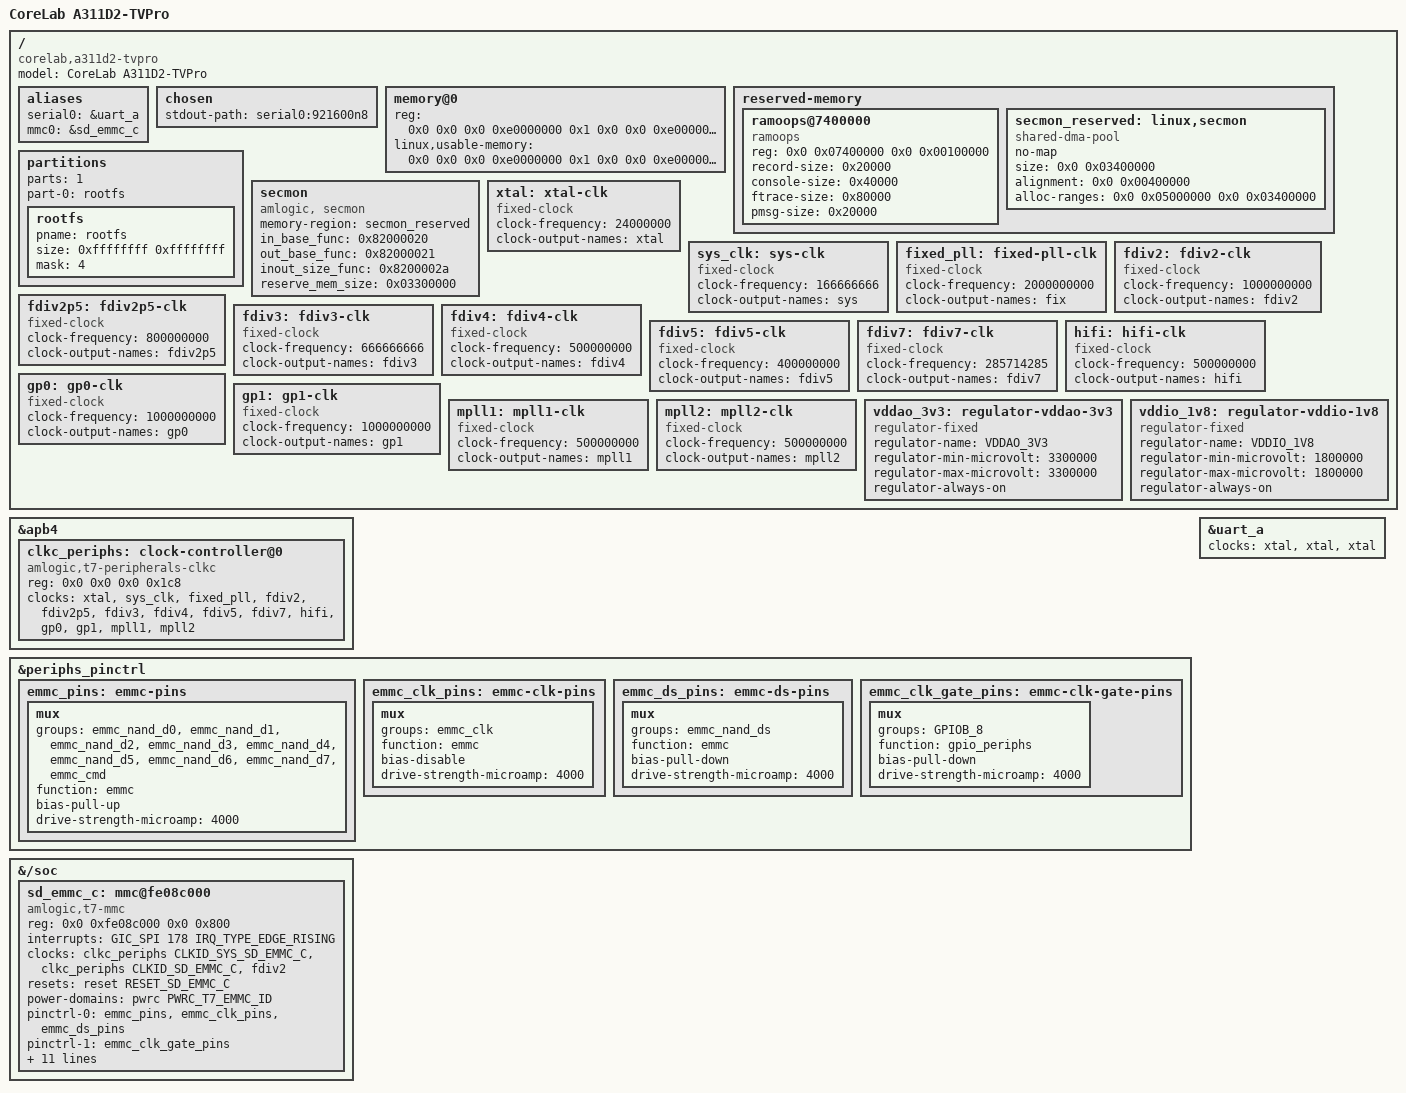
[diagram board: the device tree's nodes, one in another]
// SPDX-License-Identifier: (GPL-2.0+ OR MIT)
/*
 * Minimal Linux v7.1 TVPRO bring-up device tree.
 *
 * This intentionally starts from upstream T7 support and only carries the
 * board data needed before enabling the 5.15 vendor multimedia stack.
 */

/dts-v1/;

#include <dt-bindings/clock/amlogic,t7-peripherals-clkc.h>
#include <dt-bindings/gpio/gpio.h>
#include "amlogic-t7.dtsi"

/ {
	model = "CoreLab A311D2-TVPro";
	compatible = "corelab,a311d2-tvpro", "amlogic,a311d2", "amlogic,t7";

	aliases {
		serial0 = &uart_a;
		mmc0 = &sd_emmc_c;
	};

	chosen {
		stdout-path = "serial0:921600n8";
	};

	memory@0 {
		device_type = "memory";
		reg = <0x0 0x0 0x0 0xe0000000
		       0x1 0x0 0x0 0xe0000000
		       0x2 0x0 0x0 0x40000000>; /* 8 GB */
		linux,usable-memory = <0x0 0x0 0x0 0xe0000000
				       0x1 0x0 0x0 0xe0000000
				       0x2 0x0 0x0 0x40000000>;
	};

	reserved-memory {
		#address-cells = <2>;
		#size-cells = <2>;
		ranges;

		ramoops@7400000 {
			compatible = "ramoops";
			reg = <0x0 0x07400000 0x0 0x00100000>;
			record-size = <0x20000>;
			console-size = <0x40000>;
			ftrace-size = <0x80000>;
			pmsg-size = <0x20000>;
		};

		/* Vendor U-Boot hardcodes this node path during rsvmem check. */
		secmon_reserved: linux,secmon {
			compatible = "shared-dma-pool";
			no-map;
			size = <0x0 0x03400000>;
			alignment = <0x0 0x00400000>;
			alloc-ranges = <0x0 0x05000000 0x0 0x03400000>;
		};
	};

	partitions: partitions {
		parts = <1>;
		part-0 = <&rootfs>;

		rootfs: rootfs {
			pname = "rootfs";
			size = <0xffffffff 0xffffffff>;
			mask = <4>;
		};
	};

	secmon {
		compatible = "amlogic, secmon";
		memory-region = <&secmon_reserved>;
		in_base_func = <0x82000020>;
		out_base_func = <0x82000021>;
		inout_size_func = <0x8200002a>;
		reserve_mem_size = <0x03300000>;
	};

	xtal: xtal-clk {
		compatible = "fixed-clock";
		clock-frequency = <24000000>;
		clock-output-names = "xtal";
		#clock-cells = <0>;
	};

	/* Temporary parent clocks until the full T7 SCMI/PLL map is safe to enable. */
	sys_clk: sys-clk {
		compatible = "fixed-clock";
		clock-frequency = <166666666>;
		clock-output-names = "sys";
		#clock-cells = <0>;
	};

	fixed_pll: fixed-pll-clk {
		compatible = "fixed-clock";
		clock-frequency = <2000000000>;
		clock-output-names = "fix";
		#clock-cells = <0>;
	};

	fdiv2: fdiv2-clk {
		compatible = "fixed-clock";
		clock-frequency = <1000000000>;
		clock-output-names = "fdiv2";
		#clock-cells = <0>;
	};

	fdiv2p5: fdiv2p5-clk {
		compatible = "fixed-clock";
		clock-frequency = <800000000>;
		clock-output-names = "fdiv2p5";
		#clock-cells = <0>;
	};

	fdiv3: fdiv3-clk {
		compatible = "fixed-clock";
		clock-frequency = <666666666>;
		clock-output-names = "fdiv3";
		#clock-cells = <0>;
	};

	fdiv4: fdiv4-clk {
		compatible = "fixed-clock";
		clock-frequency = <500000000>;
		clock-output-names = "fdiv4";
		#clock-cells = <0>;
	};

	fdiv5: fdiv5-clk {
		compatible = "fixed-clock";
		clock-frequency = <400000000>;
		clock-output-names = "fdiv5";
		#clock-cells = <0>;
	};

	fdiv7: fdiv7-clk {
		compatible = "fixed-clock";
		clock-frequency = <285714285>;
		clock-output-names = "fdiv7";
		#clock-cells = <0>;
	};

	hifi: hifi-clk {
		compatible = "fixed-clock";
		clock-frequency = <500000000>;
		clock-output-names = "hifi";
		#clock-cells = <0>;
	};

	gp0: gp0-clk {
		compatible = "fixed-clock";
		clock-frequency = <1000000000>;
		clock-output-names = "gp0";
		#clock-cells = <0>;
	};

	gp1: gp1-clk {
		compatible = "fixed-clock";
		clock-frequency = <1000000000>;
		clock-output-names = "gp1";
		#clock-cells = <0>;
	};

	mpll1: mpll1-clk {
		compatible = "fixed-clock";
		clock-frequency = <500000000>;
		clock-output-names = "mpll1";
		#clock-cells = <0>;
	};

	mpll2: mpll2-clk {
		compatible = "fixed-clock";
		clock-frequency = <500000000>;
		clock-output-names = "mpll2";
		#clock-cells = <0>;
	};

	vddao_3v3: regulator-vddao-3v3 {
		compatible = "regulator-fixed";
		regulator-name = "VDDAO_3V3";
		regulator-min-microvolt = <3300000>;
		regulator-max-microvolt = <3300000>;
		regulator-always-on;
	};

	vddio_1v8: regulator-vddio-1v8 {
		compatible = "regulator-fixed";
		regulator-name = "VDDIO_1V8";
		regulator-min-microvolt = <1800000>;
		regulator-max-microvolt = <1800000>;
		regulator-always-on;
	};

};

&apb4 {
	clkc_periphs: clock-controller@0 {
		compatible = "amlogic,t7-peripherals-clkc";
		reg = <0x0 0x0 0x0 0x1c8>;
		#clock-cells = <1>;
		clocks = <&xtal>,
			 <&sys_clk>,
			 <&fixed_pll>,
			 <&fdiv2>,
			 <&fdiv2p5>,
			 <&fdiv3>,
			 <&fdiv4>,
			 <&fdiv5>,
			 <&fdiv7>,
			 <&hifi>,
			 <&gp0>,
			 <&gp1>,
			 <&mpll1>,
			 <&mpll2>;
		clock-names = "xtal",
			      "sys",
			      "fix",
			      "fdiv2",
			      "fdiv2p5",
			      "fdiv3",
			      "fdiv4",
			      "fdiv5",
			      "fdiv7",
			      "hifi",
			      "gp0",
			      "gp1",
			      "mpll1",
			      "mpll2";
	};
};

&periphs_pinctrl {
	emmc_pins: emmc-pins {
		mux {
			groups = "emmc_nand_d0",
				 "emmc_nand_d1",
				 "emmc_nand_d2",
				 "emmc_nand_d3",
				 "emmc_nand_d4",
				 "emmc_nand_d5",
				 "emmc_nand_d6",
				 "emmc_nand_d7",
				 "emmc_cmd";
			function = "emmc";
			bias-pull-up;
			drive-strength-microamp = <4000>;
		};
	};

	emmc_clk_pins: emmc-clk-pins {
		mux {
			groups = "emmc_clk";
			function = "emmc";
			bias-disable;
			drive-strength-microamp = <4000>;
		};
	};

	emmc_ds_pins: emmc-ds-pins {
		mux {
			groups = "emmc_nand_ds";
			function = "emmc";
			bias-pull-down;
			drive-strength-microamp = <4000>;
		};
	};

	emmc_clk_gate_pins: emmc-clk-gate-pins {
		mux {
			groups = "GPIOB_8";
			function = "gpio_periphs";
			bias-pull-down;
			drive-strength-microamp = <4000>;
		};
	};
};

&{/soc} {
	sd_emmc_c: mmc@fe08c000 {
		compatible = "amlogic,t7-mmc", "amlogic,meson-axg-mmc";
		reg = <0x0 0xfe08c000 0x0 0x800>;
		interrupts = <GIC_SPI 178 IRQ_TYPE_EDGE_RISING>;
		clocks = <&clkc_periphs CLKID_SYS_SD_EMMC_C>,
			 <&clkc_periphs CLKID_SD_EMMC_C>,
			 <&fdiv2>;
		clock-names = "core", "clkin0", "clkin1";
		resets = <&reset RESET_SD_EMMC_C>;
		power-domains = <&pwrc PWRC_T7_EMMC_ID>;
		pinctrl-0 = <&emmc_pins>, <&emmc_clk_pins>, <&emmc_ds_pins>;
		pinctrl-1 = <&emmc_clk_gate_pins>;
		pinctrl-names = "default", "clk-gate";
		bus-width = <8>;
		cap-mmc-highspeed;
		max-frequency = <50000000>;
		assigned-clocks = <&clkc_periphs CLKID_SD_EMMC_C>;
		assigned-clock-rates = <24000000>;
		non-removable;
		disable-wp;
		no-sd;
		no-sdio;
		vmmc-supply = <&vddao_3v3>;
		vqmmc-supply = <&vddio_1v8>;
		status = "okay";
	};
};

&uart_a {
	status = "okay";
	clocks = <&xtal>, <&xtal>, <&xtal>;
	clock-names = "xtal", "pclk", "baud";
};
